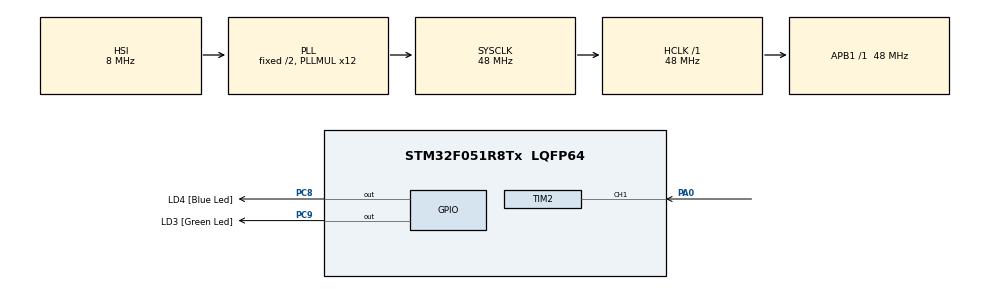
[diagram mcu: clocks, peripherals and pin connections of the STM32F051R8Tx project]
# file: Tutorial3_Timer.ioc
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Mcu.Family=STM32F0
Mcu.Name=STM32F051R8Tx
Mcu.Package=LQFP64
PA0.Signal=S_TIM2_CH1_ETR
PA13.GPIO_Label=SWDIO
PA13.Mode=Serial_Wire
PA13.Signal=SYS_SWDIO
PA14.GPIO_Label=SWCLK
PA14.Mode=Serial_Wire
PA14.Signal=SYS_SWCLK
PC8.GPIO_Label=LD4 [Blue Led]
PC8.Signal=GPIO_Output
PC9.GPIO_Label=LD3 [Green Led]
PC9.Signal=GPIO_Output
ProjectManager.HeapSize=0x200
ProjectManager.StackSize=0x400
ProjectManager.TargetToolchain=SW4STM32
RCC.AHBFreq_Value=48000000
RCC.APB1Freq_Value=48000000
RCC.APB1TimFreq_Value=48000000
RCC.HCLKFreq_Value=48000000
RCC.PLLMUL=RCC_PLL_MUL12
RCC.SYSCLKFreq_VALUE=48000000
RCC.SYSCLKSource=RCC_SYSCLKSOURCE_PLLCLK
SH.S_TIM2_CH1_ETR.0=TIM2_CH1,TriggerSource_TI1FP1
VP_TIM2_VS_ControllerModeClock.Mode=Clock Mode
VP_TIM3_VS_ClockSourceINT.Mode=Internal
board=STM32F0DISCOVERY

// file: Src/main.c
/**
  ******************************************************************************
  * File Name          : main.c
  * Description        : Main program body
  ******************************************************************************
  *
  * COPYRIGHT(c) 2016 STMicroelectronics
  *
  * Redistribution and use in source and binary forms, with or without modification,
  * are permitted provided that the following conditions are met:
  *   1. Redistributions of source code must retain the above copyright notice,
  *      this list of conditions and the following disclaimer.
  *   2. Redistributions in binary form must reproduce the above copyright notice,
  *      this list of conditions and the following disclaimer in the documentation
  *      and/or other materials provided with the distribution.
  *   3. Neither the name of STMicroelectronics nor the names of its contributors
  *      may be used to endorse or promote products derived from this software
  *      without specific prior written permission.
  *
  * THIS SOFTWARE IS PROVIDED BY THE COPYRIGHT HOLDERS AND CONTRIBUTORS "AS IS"
  * AND ANY EXPRESS OR IMPLIED WARRANTIES, INCLUDING, BUT NOT LIMITED TO, THE
  * IMPLIED WARRANTIES OF MERCHANTABILITY AND FITNESS FOR A PARTICULAR PURPOSE ARE
  * DISCLAIMED. IN NO EVENT SHALL THE COPYRIGHT HOLDER OR CONTRIBUTORS BE LIABLE
  * FOR ANY DIRECT, INDIRECT, INCIDENTAL, SPECIAL, EXEMPLARY, OR CONSEQUENTIAL
  * DAMAGES (INCLUDING, BUT NOT LIMITED TO, PROCUREMENT OF SUBSTITUTE GOODS OR
  * SERVICES; LOSS OF USE, DATA, OR PROFITS; OR BUSINESS INTERRUPTION) HOWEVER
  * CAUSED AND ON ANY THEORY OF LIABILITY, WHETHER IN CONTRACT, STRICT LIABILITY,
  * OR TORT (INCLUDING NEGLIGENCE OR OTHERWISE) ARISING IN ANY WAY OUT OF THE USE
  * OF THIS SOFTWARE, EVEN IF ADVISED OF THE POSSIBILITY OF SUCH DAMAGE.
  *
  ******************************************************************************
  */
#include "main.h"
#include "stm32f0xx_hal.h"

/* USER CODE BEGIN Includes */

#include "stm32f0308_discovery.h"

/* USER CODE END Includes */

TIM_HandleTypeDef htim2;
TIM_HandleTypeDef htim3;

/* USER CODE BEGIN PV */
/* Private variables ---------------------------------------------------------*/

uint32_t count = 0;
/* USER CODE END PV */

void SystemClock_Config(void);
void Error_Handler(void);
static void MX_GPIO_Init(void);
static void MX_TIM2_Init(void);
static void MX_TIM3_Init(void);

/* USER CODE BEGIN PFP */
/* Private function prototypes -----------------------------------------------*/

/* USER CODE END PFP */

int main(void)
{

  /* USER CODE BEGIN 1 */

	//	Prescaler: 48MHz/48000 = 1000Hz = 1ms
	//	Counter period: 500*1ms =500ms

  /* USER CODE END 1 */

  /* MCU Configuration----------------------------------------------------------*/

  /* Reset of all peripherals, Initializes the Flash interface and the Systick. */
  HAL_Init();

  /* Configure the system clock */
  SystemClock_Config();

  /* Initialize all configured peripherals */
  MX_GPIO_Init();
  MX_TIM2_Init();
  MX_TIM3_Init();

  /* USER CODE BEGIN 2 */

	HAL_TIM_Base_Start_IT(&htim3);
	HAL_TIM_Base_Start(&htim2);	//Start TIM2 without interrupt

  /* USER CODE END 2 */

  /* Infinite loop */
  /* USER CODE BEGIN WHILE */
  while (1)
  {
		count = __HAL_TIM_GetCounter(&htim2);	//read TIM2 counter value
		HAL_Delay(5000);
  /* USER CODE END WHILE */

  }

}

/** System Clock Configuration
*/
void SystemClock_Config(void)
{

  RCC_OscInitTypeDef RCC_OscInitStruct;
  RCC_ClkInitTypeDef RCC_ClkInitStruct;

    /**Initializes the CPU, AHB and APB busses clocks
    */
  RCC_OscInitStruct.OscillatorType = RCC_OSCILLATORTYPE_HSI;
  RCC_OscInitStruct.HSIState = RCC_HSI_ON;
  RCC_OscInitStruct.HSICalibrationValue = 16;
  RCC_OscInitStruct.PLL.PLLState = RCC_PLL_ON;
  RCC_OscInitStruct.PLL.PLLSource = RCC_PLLSOURCE_HSI;
  RCC_OscInitStruct.PLL.PLLMUL = RCC_PLL_MUL12;
  RCC_OscInitStruct.PLL.PREDIV = RCC_PREDIV_DIV1;
  if (HAL_RCC_OscConfig(&RCC_OscInitStruct) != HAL_OK)
  {
    Error_Handler();
  }

    /**Initializes the CPU, AHB and APB busses clocks
    */
  RCC_ClkInitStruct.ClockType = RCC_CLOCKTYPE_HCLK|RCC_CLOCKTYPE_SYSCLK
                              |RCC_CLOCKTYPE_PCLK1;
  RCC_ClkInitStruct.SYSCLKSource = RCC_SYSCLKSOURCE_PLLCLK;
  RCC_ClkInitStruct.AHBCLKDivider = RCC_SYSCLK_DIV1;
  RCC_ClkInitStruct.APB1CLKDivider = RCC_HCLK_DIV1;

  if (HAL_RCC_ClockConfig(&RCC_ClkInitStruct, FLASH_LATENCY_1) != HAL_OK)
  {
    Error_Handler();
  }

    /**Configure the Systick interrupt time
    */
  HAL_SYSTICK_Config(HAL_RCC_GetHCLKFreq()/1000);

    /**Configure the Systick
    */
  HAL_SYSTICK_CLKSourceConfig(SYSTICK_CLKSOURCE_HCLK);

  /* SysTick_IRQn interrupt configuration */
  HAL_NVIC_SetPriority(SysTick_IRQn, 0, 0);
}

/* TIM2 init function */
static void MX_TIM2_Init(void)
{

  TIM_SlaveConfigTypeDef sSlaveConfig;
  TIM_MasterConfigTypeDef sMasterConfig;

  htim2.Instance = TIM2;
  htim2.Init.Prescaler = 0;
  htim2.Init.CounterMode = TIM_COUNTERMODE_UP;
  htim2.Init.Period = 0;
  htim2.Init.ClockDivision = TIM_CLOCKDIVISION_DIV1;
  if (HAL_TIM_Base_Init(&htim2) != HAL_OK)
  {
    Error_Handler();
  }

  sSlaveConfig.SlaveMode = TIM_SLAVEMODE_EXTERNAL1;
  sSlaveConfig.InputTrigger = TIM_TS_TI1FP1;
  sSlaveConfig.TriggerPolarity = TIM_TRIGGERPOLARITY_RISING;
  sSlaveConfig.TriggerFilter = 0;
  if (HAL_TIM_SlaveConfigSynchronization(&htim2, &sSlaveConfig) != HAL_OK)
  {
    Error_Handler();
  }

  sMasterConfig.MasterOutputTrigger = TIM_TRGO_RESET;
  sMasterConfig.MasterSlaveMode = TIM_MASTERSLAVEMODE_DISABLE;
  if (HAL_TIMEx_MasterConfigSynchronization(&htim2, &sMasterConfig) != HAL_OK)
  {
    Error_Handler();
  }

}

/* TIM3 init function */
static void MX_TIM3_Init(void)
{

  TIM_ClockConfigTypeDef sClockSourceConfig;
  TIM_MasterConfigTypeDef sMasterConfig;

  htim3.Instance = TIM3;
  htim3.Init.Prescaler = 0;
  htim3.Init.CounterMode = TIM_COUNTERMODE_UP;
  htim3.Init.Period = 0;
  htim3.Init.ClockDivision = TIM_CLOCKDIVISION_DIV1;
  if (HAL_TIM_Base_Init(&htim3) != HAL_OK)
  {
    Error_Handler();
  }

  sClockSourceConfig.ClockSource = TIM_CLOCKSOURCE_INTERNAL;
  if (HAL_TIM_ConfigClockSource(&htim3, &sClockSourceConfig) != HAL_OK)
  {
    Error_Handler();
  }

  sMasterConfig.MasterOutputTrigger = TIM_TRGO_RESET;
  sMasterConfig.MasterSlaveMode = TIM_MASTERSLAVEMODE_DISABLE;
  if (HAL_TIMEx_MasterConfigSynchronization(&htim3, &sMasterConfig) != HAL_OK)
  {
    Error_Handler();
  }

}

/** Configure pins as
        * Analog
        * Input
        * Output
        * EVENT_OUT
        * EXTI
*/
static void MX_GPIO_Init(void)
{

  GPIO_InitTypeDef GPIO_InitStruct;

  /* GPIO Ports Clock Enable */
  __HAL_RCC_GPIOA_CLK_ENABLE();
  __HAL_RCC_GPIOC_CLK_ENABLE();

  /*Configure GPIO pin Output Level */
  HAL_GPIO_WritePin(GPIOC, LD4_Pin|LD3_Pin, GPIO_PIN_RESET);

  /*Configure GPIO pins : LD4_Pin LD3_Pin */
  GPIO_InitStruct.Pin = LD4_Pin|LD3_Pin;
  GPIO_InitStruct.Mode = GPIO_MODE_OUTPUT_PP;
  GPIO_InitStruct.Pull = GPIO_NOPULL;
  GPIO_InitStruct.Speed = GPIO_SPEED_FREQ_LOW;
  HAL_GPIO_Init(GPIOC, &GPIO_InitStruct);

}

/* USER CODE BEGIN 4 */

/* Timer Interrupt CallBack */
void HAL_TIM_PeriodElapsedCallback(TIM_HandleTypeDef *htim)
{
	if (htim->Instance==TIM3) //check if the interrupt comes from TIM3
		{
			//HAL_GPIO_TogglePin(GPIOC, GPIO_PIN_9);
			BSP_LED_Toggle(LED_GREEN);
		}
}

/* USER CODE END 4 */

void Error_Handler(void)
{
  /* USER CODE BEGIN Error_Handler */
  /* User can add his own implementation to report the HAL error return state */
  while(1)
  {
		BSP_LED_Toggle(LED_BLUE);
		HAL_Delay(200);
  }
  /* USER CODE END Error_Handler */
}

/************************ (C) COPYRIGHT STMicroelectronics *****END OF FILE****/
